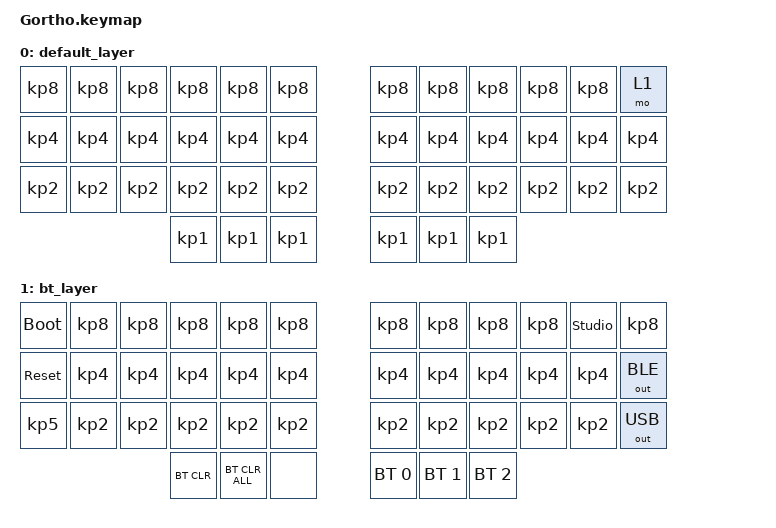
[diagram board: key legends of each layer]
#include <behaviors.dtsi>
#include <dt-bindings/zmk/keys.h>
#include <dt-bindings/zmk/bt.h>
#include <dt-bindings/zmk/outputs.h>


/ {  
    keymap {
        compatible = "zmk,keymap";

        default_layer {
            bindings = <
                &kp KP_N8     &kp KP_N8     &kp KP_N8     &kp KP_N8     &kp KP_N8     &kp KP_N8     &kp KP_N8     &kp KP_N8     &kp KP_N8     &kp KP_N8     &kp KP_N8     &mo 1
                &kp KP_N4     &kp KP_N4     &kp KP_N4     &kp KP_N4     &kp KP_N4     &kp KP_N4     &kp KP_N4     &kp KP_N4     &kp KP_N4     &kp KP_N4     &kp KP_N4     &kp KP_N4
                &kp KP_N2     &kp KP_N2     &kp KP_N2     &kp KP_N2     &kp KP_N2     &kp KP_N2     &kp KP_N2     &kp KP_N2     &kp KP_N2     &kp KP_N2     &kp KP_N2     &kp KP_N2
                                                          &kp KP_N1     &kp KP_N1     &kp KP_N1     &kp KP_N1     &kp KP_N1     &kp KP_N1
            >;
        };
        
        bt_layer {
            bindings = <
                &bootloader   &kp KP_N8     &kp KP_N8     &kp KP_N8     &kp KP_N8     &kp KP_N8     &kp KP_N8     &kp KP_N8     &kp KP_N8     &kp KP_N8     &studio_unlock     &kp KP_N8
                &sys_reset    &kp KP_N4     &kp KP_N4     &kp KP_N4     &kp KP_N4     &kp KP_N4     &kp KP_N4     &kp KP_N4     &kp KP_N4     &kp KP_N4     &kp KP_N4     &out OUT_BLE
                &kp KP_N5     &kp KP_N2     &kp KP_N2     &kp KP_N2     &kp KP_N2     &kp KP_N2     &kp KP_N2     &kp KP_N2     &kp KP_N2     &kp KP_N2     &kp KP_N2     &out OUT_USB
                                                          &bt BT_CLR    &bt BT_CLR_ALL&none         &bt BT_SEL 0  &bt BT_SEL 1  &bt BT_SEL 2
            >;
        };
    };
};
